# EZR32HG320F32R69 register map
File version: 4.0.0
CPU: CM0PLUS r0p1, little endian, no MPU, no FPU, 3 interrupt priority bits
Registers are 32-bit, read-write, reset 0x0 unless marked. A register's access mark holds for its fields unless they carry their own. Offsets are from the block's base; [hi:lo] are bit positions; {n}, {i} and the like mark numbered series.

## PRS
Base 0x400CC000
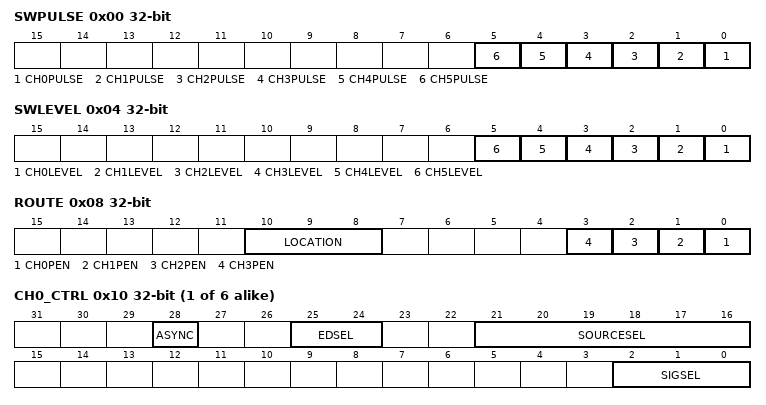
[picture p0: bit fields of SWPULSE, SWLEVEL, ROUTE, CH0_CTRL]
0x00 SWPULSE wo — Software Pulse Register
  [n] CH{n}PULSE (n=0..5) — Channel {n} Pulse Generation
0x04 SWLEVEL — Software Level Register
  [n] CH{n}LEVEL (n=0..5) — Channel {n} Software Level
0x08 ROUTE — I/O Routing Register
  [10:8] LOCATION — I/O Location
    {v}=LOC{v} (Location {v}) (v=0..3)
  [n] CH{n}PEN (n=0..3) — CH{n} Pin Enable
{0x10+4i} CH{i}_CTRL (i=0..5) — Channel Control Register
  [28] ASYNC — Asynchronous reflex
  [25:24] EDSEL — Edge Detect Select
    0=OFF (Signal is left as it is); 1=POSEDGE (A one HFPERCLK cycle pulse is generated for every positive edge of the incoming signal); 2=NEGEDGE (A one HFPERCLK clock cycle pulse is generated for every negative edge of the incoming signal); 3=BOTHEDGES (A one HFPERCLK clock cycle pulse is generated for every edge of the incoming signal)
  [21:16] SOURCESEL — Source Select
    0=NONE (No source selected); 1=VCMP (Voltage Comparator); 8=ADC0 (Analog to Digital Converter 0); 16=USART0 (Universal Synchronous/Asynchronous Receiver/Transmitter 0); 17=USARTRF1 (Universal Synchronous/Asynchronous Receiver/Transmitter 1); 28=TIMER0; 29=TIMER1; 30=TIMER2; 36=USB (Universal Serial Bus Interface); 40=RTC (Real-Time Counter); 48=GPIOL (General purpose Input/Output); 49=GPIOH (General purpose Input/Output); 54=PCNT0 (Pulse Counter 0)
  [2:0] SIGSEL — Signal Select
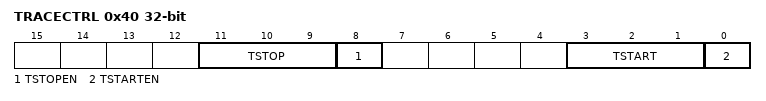
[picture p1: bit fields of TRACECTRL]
0x40 TRACECTRL — MTB Trace Control Register
  [11:9] TSTOP — MTB TSTOP PRS select
    {v}=PRSCH{v} (PRS ch {v} is controlling TSTOP.) (v=0..5)
  [8] TSTOPEN — PRS TSTOP Enable
  [3:1] TSTART — MTB TSTART PRS select
    {v}=PRSCH{v} (PRS ch {v} is controlling TSTART.) (v=0..5)
  [0] TSTARTEN — PRS TSTART Enable

## IDAC0
Base 0x40004000
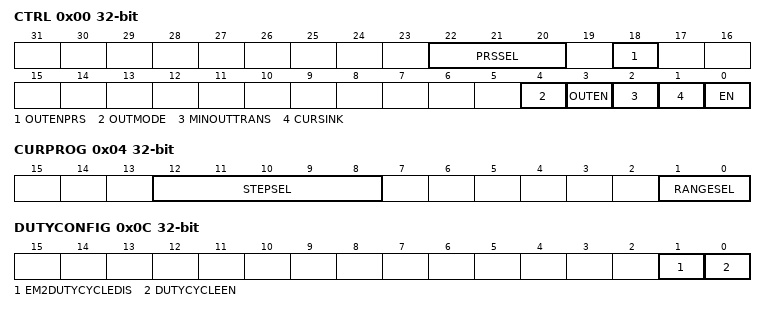
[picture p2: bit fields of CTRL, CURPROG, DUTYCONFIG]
0x00 CTRL — Control Register
  [22:20] PRSSEL — IDAC Output PRS channnel Select
    {v}=PRSCH{v} (PRS Channel {v} selected.) (v=0..5)
  [18] OUTENPRS — PRS Controlled Output Enable
  [4] OUTMODE — Output Modes
  [3] OUTEN — Output Enable
  [2] MINOUTTRANS — Minimum Output Transition Enable
  [1] CURSINK — Current Sink Enable
  [0] EN — Current DAC Enable
0x04 CURPROG — Current Programming Register
  [12:8] STEPSEL — Current Step Size Select
  [1:0] RANGESEL — Current Range Select
    0=RANGE0 (Current range set to 0 - 1.6 uA.); 1=RANGE1 (Current range set to 1.6 - 4.7 uA.); 2=RANGE2 (Current range set to 0.5 - 16 uA.); 3=RANGE3 (Current range set to 2 - 64 uA.)
0x08 CAL — Calibration Register
  [6:0] TUNING — Tune the current to given accuracy
0x0C DUTYCONFIG — Duty Cycle Configauration Register
  [1] EM2DUTYCYCLEDIS — EM2/EM3 Duty Cycle Disable.
  [0] DUTYCYCLEEN — Duty Cycle Enable.

## VCMP
Base 0x40000000
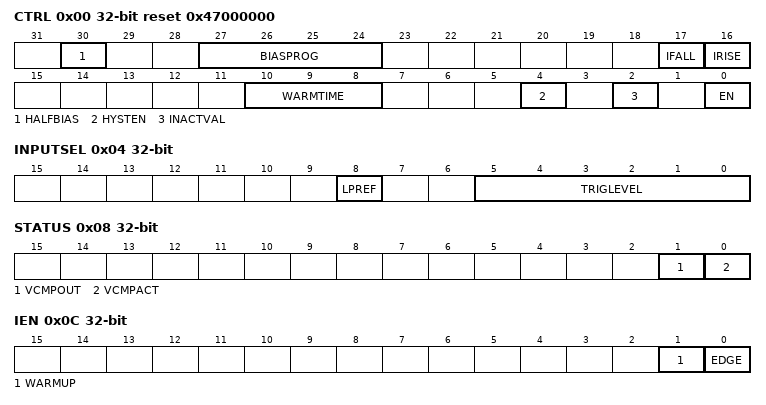
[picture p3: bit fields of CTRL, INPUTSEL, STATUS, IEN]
0x00 CTRL reset 0x47000000 — Control Register
  [30] HALFBIAS — Half Bias Current
  [27:24] BIASPROG — VCMP Bias Programming Value
  [17] IFALL — Falling Edge Interrupt Sense
  [16] IRISE — Rising Edge Interrupt Sense
  [10:8] WARMTIME — Warm-Up Time
    0=4CYCLES (4 HFPERCLK cycles); 1=8CYCLES (8 HFPERCLK cycles); 2=16CYCLES (16 HFPERCLK cycles); 3=32CYCLES (32 HFPERCLK cycles); 4=64CYCLES (64 HFPERCLK cycles); 5=128CYCLES (128 HFPERCLK cycles); 6=256CYCLES (256 HFPERCLK cycles); 7=512CYCLES (512 HFPERCLK cycles)
  [4] HYSTEN — Hysteresis Enable
  [2] INACTVAL — Inactive Value
  [0] EN — Voltage Supply Comparator Enable
0x04 INPUTSEL — Input Selection Register
  [8] LPREF — Low Power Reference
  [5:0] TRIGLEVEL — Trigger Level
0x08 STATUS ro
  [1] VCMPOUT — Voltage Supply Comparator Output
  [0] VCMPACT — Voltage Supply Comparator Active
0x0C IEN — Interrupt Enable Register
  [1] WARMUP — Warm-up Interrupt Enable
  [0] EDGE — Edge Trigger Interrupt Enable
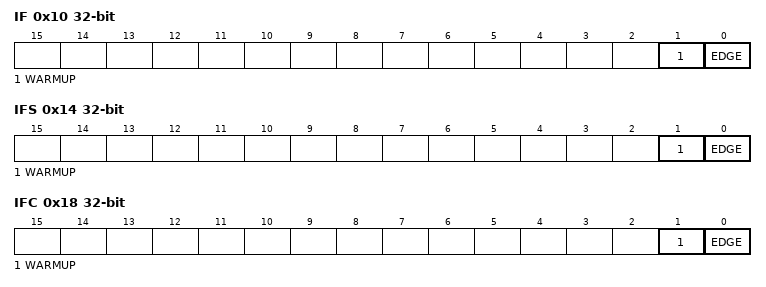
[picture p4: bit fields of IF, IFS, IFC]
0x10 IF ro — Interrupt Flag Register
  [1] WARMUP — Warm-up Interrupt Flag
  [0] EDGE — Edge Triggered Interrupt Flag
0x14 IFS wo — Interrupt Flag Set Register
  [1] WARMUP — Warm-up Interrupt Flag Set
  [0] EDGE — Edge Triggered Interrupt Flag Set
0x18 IFC wo — Interrupt Flag Clear Register
  [1] WARMUP — Warm-up Interrupt Flag Clear
  [0] EDGE — Edge Triggered Interrupt Flag Clear

## RTC
Base 0x40080000
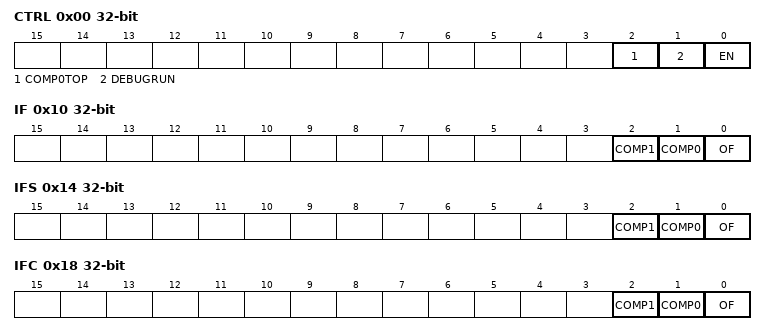
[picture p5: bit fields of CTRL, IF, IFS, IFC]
0x00 CTRL — Control Register
  [2] COMP0TOP — Compare Channel 0 is Top Value
  [1] DEBUGRUN — Debug Mode Run Enable
  [0] EN — RTC Enable
0x04 CNT — Counter Value Register
  [23:0] CNT — Counter Value
0x08 COMP0 — Compare Value Register 0
  [23:0] COMP0 — Compare Value 0
0x0C COMP1 — Compare Value Register 1
  [23:0] COMP1 — Compare Value 1
0x10 IF ro — Interrupt Flag Register
  [2] COMP1 — Compare Match 1 Interrupt Flag
  [1] COMP0 — Compare Match 0 Interrupt Flag
  [0] OF — Overflow Interrupt Flag
0x14 IFS wo — Interrupt Flag Set Register
  [2] COMP1 — Set Compare match 1 Interrupt Flag
  [1] COMP0 — Set Compare match 0 Interrupt Flag
  [0] OF — Set Overflow Interrupt Flag
0x18 IFC wo — Interrupt Flag Clear Register
  [2] COMP1 — Clear Compare match 1 Interrupt Flag
  [1] COMP0 — Clear Compare match 0 Interrupt Flag
  [0] OF — Clear Overflow Interrupt Flag
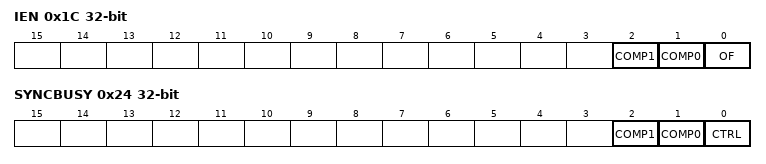
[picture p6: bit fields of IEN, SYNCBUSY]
0x1C IEN — Interrupt Enable Register
  [2] COMP1 — Compare Match 1 Interrupt Enable
  [1] COMP0 — Compare Match 0 Interrupt Enable
  [0] OF — Overflow Interrupt Enable
0x20 FREEZE
  [0] REGFREEZE — Register Update Freeze
0x24 SYNCBUSY ro — Synchronization Busy Register
  [2] COMP1 — COMP1 Register Busy
  [1] COMP0 — COMP0 Register Busy
  [0] CTRL — CTRL Register Busy

## WDOG
Base 0x40088000
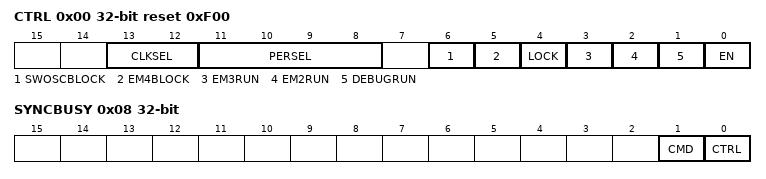
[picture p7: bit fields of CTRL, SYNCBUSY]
0x00 CTRL reset 0xF00 — Control Register
  [13:12] CLKSEL — Watchdog Clock Select
    0=ULFRCO; 1=LFRCO; 2=LFXO
  [11:8] PERSEL — Watchdog Timeout Period Select
  [6] SWOSCBLOCK — Software Oscillator Disable Block
  [5] EM4BLOCK — Energy Mode 4 Block
  [4] LOCK — Configuration lock
  [3] EM3RUN — Energy Mode 3 Run Enable
  [2] EM2RUN — Energy Mode 2 Run Enable
  [1] DEBUGRUN — Debug Mode Run Enable
  [0] EN — Watchdog Timer Enable
0x04 CMD wo — Command Register
  [0] CLEAR — Watchdog Timer Clear
0x08 SYNCBUSY ro — Synchronization Busy Register
  [1] CMD — CMD Register Busy
  [0] CTRL — CTRL Register Busy

## MTB
Base 0xF0040000
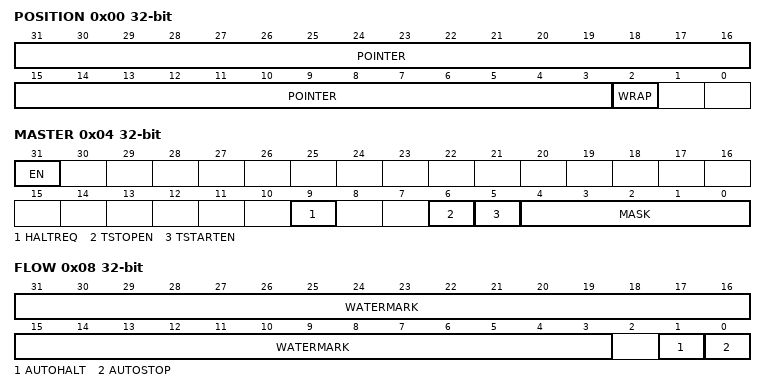
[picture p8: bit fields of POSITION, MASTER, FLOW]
0x00 POSITION — MTB Trace Position Register.
  [31:3] POINTER — Trace packet location pointer.
  [2] WRAP — Trace wrap bit.
0x04 MASTER — MTB Trace Control Register
  [31] EN — Main trace enable bit.
  [9] HALTREQ — Halt request bit.
  [6] TSTOPEN — Trace stop input enable.
  [5] TSTARTEN — Trace start input enable.
  [4:0] MASK — This value determines the maximum size of the trace buffer in SRAM.
0x08 FLOW — MTB Trace Flow Register
  [31:3] WATERMARK — WATERMARK value.
  [1] AUTOHALT — AUTOHALT enable.
  [0] AUTOSTOP — AUTOSTOP enable.
0x0C BASE reset 0x20000000 — MTB Trace Base Register
  [31:0] BASE — The ram base address.

## Notices in the file
# License
Copyright 2021 Silicon Laboratories Inc. www.silabs.com
SPDX-License-Identifier: Zlib
The licensor of this software is Silicon Laboratories Inc.
This software is provided 'as-is', without any express or implied
warranty. In no event will the authors be held liable for any damages
arising from the use of this software.
Permission is granted to anyone to use this software for any purpose,
including commercial applications, and to alter it and redistribute it
freely, subject to the following restrictions:
1. The origin of this software must not be misrepresented; you must not
claim that you wrote the original software. If you use this software
in a product, an acknowledgment in the product documentation would be
appreciated but is not required.
2. Altered source versions must be plainly marked as such, and must not be
misrepresented as being the original software.
3. This notice may not be removed or altered from any source distribution.
